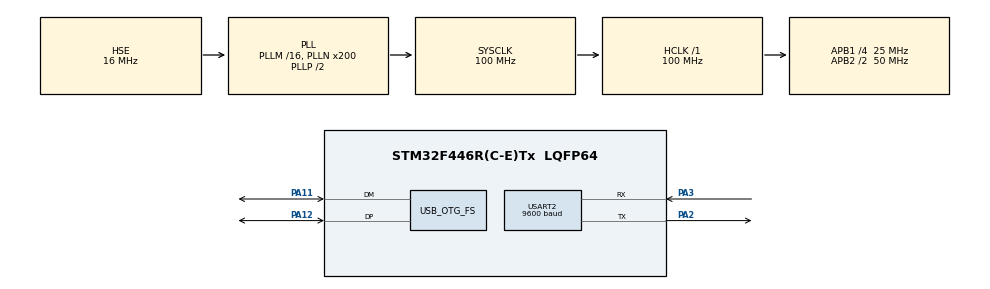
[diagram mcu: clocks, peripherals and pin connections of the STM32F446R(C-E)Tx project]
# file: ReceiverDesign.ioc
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Dma.Request0=USART2_RX
Dma.Request1=USART2_TX
Dma.USART2_RX.0.Direction=DMA_PERIPH_TO_MEMORY
Dma.USART2_RX.0.FIFOMode=DMA_FIFOMODE_DISABLE
Dma.USART2_RX.0.Instance=DMA1_Stream5
Dma.USART2_RX.0.MemDataAlignment=DMA_MDATAALIGN_BYTE
Dma.USART2_RX.0.MemInc=DMA_MINC_ENABLE
Dma.USART2_RX.0.Mode=DMA_CIRCULAR
Dma.USART2_RX.0.PeriphDataAlignment=DMA_PDATAALIGN_BYTE
Dma.USART2_RX.0.PeriphInc=DMA_PINC_DISABLE
Dma.USART2_RX.0.Priority=DMA_PRIORITY_LOW
Dma.USART2_TX.1.Direction=DMA_MEMORY_TO_PERIPH
Dma.USART2_TX.1.FIFOMode=DMA_FIFOMODE_DISABLE
Dma.USART2_TX.1.Instance=DMA1_Stream6
Dma.USART2_TX.1.MemDataAlignment=DMA_MDATAALIGN_BYTE
Dma.USART2_TX.1.MemInc=DMA_MINC_ENABLE
Dma.USART2_TX.1.Mode=DMA_NORMAL
Dma.USART2_TX.1.PeriphDataAlignment=DMA_PDATAALIGN_BYTE
Dma.USART2_TX.1.PeriphInc=DMA_PINC_DISABLE
Dma.USART2_TX.1.Priority=DMA_PRIORITY_LOW
Mcu.Family=STM32F4
Mcu.Name=STM32F446R(C-E)Tx
Mcu.Package=LQFP64
NVIC.DMA1_Stream5_IRQn=true\:0\:0\:false\:false\:true\:false\:true\:true
NVIC.DMA1_Stream6_IRQn=true\:0\:0\:false\:false\:true\:false\:true\:true
NVIC.OTG_FS_IRQn=true\:0\:0\:false\:false\:true\:true\:true\:true
NVIC.PriorityGroup=NVIC_PRIORITYGROUP_4
NVIC.USART2_IRQn=true\:0\:0\:false\:false\:true\:true\:true\:true
PA11.Mode=Device_Only
PA11.Signal=USB_OTG_FS_DM
PA12.Mode=Device_Only
PA12.Signal=USB_OTG_FS_DP
PA2.Mode=Asynchronous
PA2.Signal=USART2_TX
PA3.GPIO_PuPd=GPIO_PULLUP
PA3.Mode=Asynchronous
PA3.Signal=USART2_RX
PH0-OSC_IN.Mode=HSE-External-Oscillator
PH0-OSC_IN.Signal=RCC_OSC_IN
PH1-OSC_OUT.Mode=HSE-External-Oscillator
PH1-OSC_OUT.Signal=RCC_OSC_OUT
ProjectManager.HeapSize=0x200
ProjectManager.StackSize=0x400
ProjectManager.TargetToolchain=STM32CubeIDE
RCC.AHBFreq_Value=100000000
RCC.APB1CLKDivider=RCC_HCLK_DIV4
RCC.APB1Freq_Value=25000000
RCC.APB1TimFreq_Value=50000000
RCC.APB2CLKDivider=RCC_HCLK_DIV2
RCC.APB2Freq_Value=50000000
RCC.APB2TimFreq_Value=100000000
RCC.CortexFreq_Value=100000000
RCC.HCLKFreq_Value=100000000
RCC.HSE_VALUE=16000000
RCC.PLLN=200
RCC.PLLQ=4
RCC.PLLSAIP=RCC_PLLSAIP_DIV4
RCC.SYSCLKFreq_VALUE=100000000
RCC.SYSCLKSource=RCC_SYSCLKSOURCE_PLLCLK
RCC.USBCLockSelection=RCC_CLK48CLKSOURCE_PLLSAIP
RCC.USBFreq_Value=48000000
RCC.VCOOutputFreq_Value=200000000
USART2.BaudRate=9600
USART2.VirtualMode=VM_ASYNC
USB_OTG_FS.VirtualMode=Device_Only
board=custom

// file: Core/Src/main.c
/* USER CODE BEGIN Header */
/**
  ******************************************************************************
  * @file           : main.c
  * @brief          : Main program body
  ******************************************************************************
  * @attention
  *
  * Copyright (c) 2025 STMicroelectronics.
  * All rights reserved.
  *
  * This software is licensed under terms that can be found in the LICENSE file
  * in the root directory of this software component.
  * If no LICENSE file comes with this software, it is provided AS-IS.
  *
  ******************************************************************************
  */
/* USER CODE END Header */
#include "main.h"

UART_HandleTypeDef huart2;
DMA_HandleTypeDef hdma_usart2_rx;
DMA_HandleTypeDef hdma_usart2_tx;

PCD_HandleTypeDef hpcd_USB_OTG_FS;

void SystemClock_Config(void);
static void MX_GPIO_Init(void);
static void MX_DMA_Init(void);
static void MX_USART2_UART_Init(void);
static void MX_USB_OTG_FS_PCD_Init(void);

/* USER CODE BEGIN 0 */
uint32_t tusb_time_millis_api(void) {
	return HAL_GetTick();
}

volatile bool msc_device = false;
volatile bool hid_device = false;
queue_t incoming_queue = {};
queue_t outgoing_queue = {};
bool msc_response_ready = false;
bool tx_pending = false;

/* USER CODE END 0 */

int main(void)
{

  /* MCU Configuration--------------------------------------------------------*/

  /* Reset of all peripherals, Initializes the Flash interface and the Systick. */
  HAL_Init();

  /* Configure the system clock */
  SystemClock_Config();

  /* Initialize all configured peripherals */
  MX_GPIO_Init();
  MX_DMA_Init();
  MX_USART2_UART_Init();
  MX_USB_OTG_FS_PCD_Init();
  /* USER CODE BEGIN 2 */
  tud_init(0);
  uart_rx_init();

  /* USER CODE END 2 */

  /* Infinite loop */
  /* USER CODE BEGIN WHILE */
  while (1)
  {
	  tud_task();
	  uart_rx_service_receiver();
	  uart_tx_service_receiver();
	  hid_task();
    /* USER CODE END WHILE */

  }
}

void SystemClock_Config(void)
{
  RCC_OscInitTypeDef RCC_OscInitStruct = {0};
  RCC_ClkInitTypeDef RCC_ClkInitStruct = {0};

  /** Configure the main internal regulator output voltage
  */
  __HAL_RCC_PWR_CLK_ENABLE();
  __HAL_PWR_VOLTAGESCALING_CONFIG(PWR_REGULATOR_VOLTAGE_SCALE3);

  /** Initializes the RCC Oscillators according to the specified parameters
  * in the RCC_OscInitTypeDef structure.
  */
  RCC_OscInitStruct.OscillatorType = RCC_OSCILLATORTYPE_HSE;
  RCC_OscInitStruct.HSEState = RCC_HSE_ON;
  RCC_OscInitStruct.PLL.PLLState = RCC_PLL_ON;
  RCC_OscInitStruct.PLL.PLLSource = RCC_PLLSOURCE_HSE;
  RCC_OscInitStruct.PLL.PLLM = 16;
  RCC_OscInitStruct.PLL.PLLN = 200;
  RCC_OscInitStruct.PLL.PLLP = RCC_PLLP_DIV2;
  RCC_OscInitStruct.PLL.PLLQ = 4;
  RCC_OscInitStruct.PLL.PLLR = 2;
  if (HAL_RCC_OscConfig(&RCC_OscInitStruct) != HAL_OK)
  {
    Error_Handler();
  }

  /** Initializes the CPU, AHB and APB buses clocks
  */
  RCC_ClkInitStruct.ClockType = RCC_CLOCKTYPE_HCLK|RCC_CLOCKTYPE_SYSCLK
                              |RCC_CLOCKTYPE_PCLK1|RCC_CLOCKTYPE_PCLK2;
  RCC_ClkInitStruct.SYSCLKSource = RCC_SYSCLKSOURCE_PLLCLK;
  RCC_ClkInitStruct.AHBCLKDivider = RCC_SYSCLK_DIV1;
  RCC_ClkInitStruct.APB1CLKDivider = RCC_HCLK_DIV4;
  RCC_ClkInitStruct.APB2CLKDivider = RCC_HCLK_DIV2;

  if (HAL_RCC_ClockConfig(&RCC_ClkInitStruct, FLASH_LATENCY_3) != HAL_OK)
  {
    Error_Handler();
  }
}

static void MX_USART2_UART_Init(void)
{

  huart2.Instance = USART2;
  huart2.Init.BaudRate = 9600;
  huart2.Init.WordLength = UART_WORDLENGTH_8B;
  huart2.Init.StopBits = UART_STOPBITS_1;
  huart2.Init.Parity = UART_PARITY_NONE;
  huart2.Init.Mode = UART_MODE_TX_RX;
  huart2.Init.HwFlowCtl = UART_HWCONTROL_NONE;
  huart2.Init.OverSampling = UART_OVERSAMPLING_16;
  if (HAL_UART_Init(&huart2) != HAL_OK)
  {
    Error_Handler();
  }

}

static void MX_USB_OTG_FS_PCD_Init(void)
{

  hpcd_USB_OTG_FS.Instance = USB_OTG_FS;
  hpcd_USB_OTG_FS.Init.dev_endpoints = 6;
  hpcd_USB_OTG_FS.Init.speed = PCD_SPEED_FULL;
  hpcd_USB_OTG_FS.Init.dma_enable = DISABLE;
  hpcd_USB_OTG_FS.Init.phy_itface = PCD_PHY_EMBEDDED;
  hpcd_USB_OTG_FS.Init.Sof_enable = DISABLE;
  hpcd_USB_OTG_FS.Init.low_power_enable = DISABLE;
  hpcd_USB_OTG_FS.Init.lpm_enable = DISABLE;
  hpcd_USB_OTG_FS.Init.vbus_sensing_enable = DISABLE;
  hpcd_USB_OTG_FS.Init.use_dedicated_ep1 = DISABLE;
  if (HAL_PCD_Init(&hpcd_USB_OTG_FS) != HAL_OK)
  {
    Error_Handler();
  }

}

static void MX_DMA_Init(void)
{

  /* DMA controller clock enable */
  __HAL_RCC_DMA1_CLK_ENABLE();

  /* DMA interrupt init */
  /* DMA1_Stream5_IRQn interrupt configuration */
  HAL_NVIC_SetPriority(DMA1_Stream5_IRQn, 0, 0);
  HAL_NVIC_EnableIRQ(DMA1_Stream5_IRQn);
  /* DMA1_Stream6_IRQn interrupt configuration */
  HAL_NVIC_SetPriority(DMA1_Stream6_IRQn, 0, 0);
  HAL_NVIC_EnableIRQ(DMA1_Stream6_IRQn);

}

static void MX_GPIO_Init(void)
{

  /* GPIO Ports Clock Enable */
  __HAL_RCC_GPIOH_CLK_ENABLE();
  __HAL_RCC_GPIOA_CLK_ENABLE();

}

void Error_Handler(void)
{
  __disable_irq();
  while (1)
  {
  }
}
